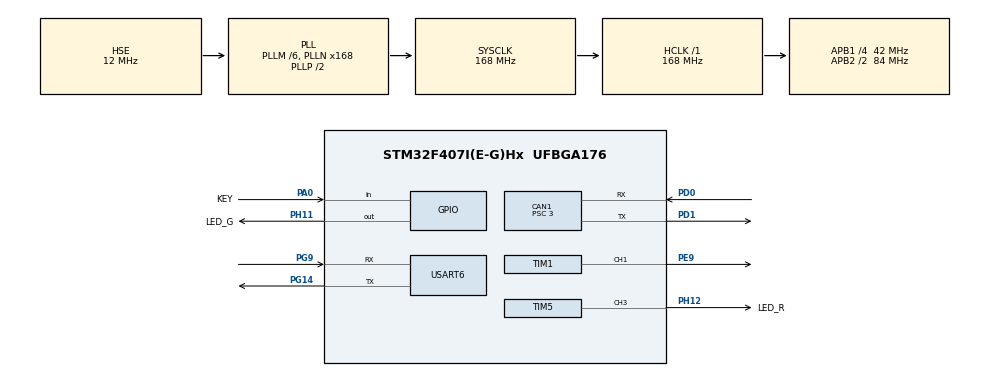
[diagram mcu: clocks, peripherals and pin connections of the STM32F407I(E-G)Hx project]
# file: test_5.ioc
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CAN1.ABOM=ENABLE
CAN1.BS1=CAN_BS1_11TQ
CAN1.BS2=CAN_BS2_2TQ
CAN1.CalculateBaudRate=1000000
CAN1.CalculateTimeBit=1000
CAN1.CalculateTimeQuantum=71.42857142857143
CAN1.NART=ENABLE
CAN1.Prescaler=3
Dma.Request0=USART6_RX
Dma.USART6_RX.0.Direction=DMA_PERIPH_TO_MEMORY
Dma.USART6_RX.0.FIFOMode=DMA_FIFOMODE_DISABLE
Dma.USART6_RX.0.Instance=DMA2_Stream1
Dma.USART6_RX.0.MemDataAlignment=DMA_MDATAALIGN_BYTE
Dma.USART6_RX.0.MemInc=DMA_MINC_ENABLE
Dma.USART6_RX.0.Mode=DMA_NORMAL
Dma.USART6_RX.0.PeriphDataAlignment=DMA_PDATAALIGN_BYTE
Dma.USART6_RX.0.PeriphInc=DMA_PINC_DISABLE
Dma.USART6_RX.0.Priority=DMA_PRIORITY_LOW
FREERTOS.Tasks01=motorTask,1,256,StartMotorTask,Default,NULL,Dynamic,NULL,NULL;uartTask,0,512,StartUartTask,Default,NULL,Dynamic,NULL,NULL;servoTask,0,256,StartServoTask,Default,NULL,Dynamic,NULL,NULL;ledTask,-1,256,StartLedTask,Default,NULL,Dynamic,NULL,NULL
FREERTOS.configTOTAL_HEAP_SIZE=24576
Mcu.Family=STM32F4
Mcu.Name=STM32F407I(E-G)Hx
Mcu.Package=UFBGA176
NVIC.CAN1_RX0_IRQn=true\:5\:0\:false\:false\:true\:true\:true\:true\:true
NVIC.DMA2_Stream1_IRQn=true\:5\:0\:false\:false\:true\:true\:false\:true\:true
NVIC.PriorityGroup=NVIC_PRIORITYGROUP_4
NVIC.TIM6_DAC_IRQn=true\:15\:0\:false\:false\:true\:true\:false\:true\:true
NVIC.USART6_IRQn=true\:5\:0\:false\:false\:true\:true\:false\:true\:true
PA0.GPIO_Label=KEY
PA0.GPIO_PuPd=GPIO_PULLUP
PA0.Signal=GPIO_Input
PA13.Mode=Serial_Wire
PA13.Signal=SYS_JTMS-SWDIO
PA14.Mode=Serial_Wire
PA14.Signal=SYS_JTCK-SWCLK
PD0.Mode=CAN_Activate
PD0.Signal=CAN1_RX
PD1.Mode=CAN_Activate
PD1.Signal=CAN1_TX
PE9.Signal=S_TIM1_CH1
PG14.Mode=Asynchronous
PG14.Signal=USART6_TX
PG9.Mode=Asynchronous
PG9.Signal=USART6_RX
PH0-OSC_IN.Mode=HSE-External-Oscillator
PH0-OSC_IN.Signal=RCC_OSC_IN
PH1-OSC_OUT.Mode=HSE-External-Oscillator
PH1-OSC_OUT.Signal=RCC_OSC_OUT
PH11.GPIO_Label=LED_G
PH11.Signal=GPIO_Output
PH12.GPIO_Label=LED_R
PH12.Signal=S_TIM5_CH3
ProjectManager.HeapSize=0x200
ProjectManager.StackSize=0x400
ProjectManager.TargetToolchain=CMake
RCC.48MHZClocksFreq_Value=48000000
RCC.AHBFreq_Value=168000000
RCC.APB1CLKDivider=RCC_HCLK_DIV4
RCC.APB1Freq_Value=42000000
RCC.APB1TimFreq_Value=84000000
RCC.APB2CLKDivider=RCC_HCLK_DIV2
RCC.APB2Freq_Value=84000000
RCC.APB2TimFreq_Value=168000000
RCC.CortexFreq_Value=168000000
RCC.HCLKFreq_Value=168000000
RCC.HSE_VALUE=12000000
RCC.HSI_VALUE=16000000
RCC.LSE_VALUE=32768
RCC.PLLM=6
RCC.PLLN=168
RCC.PLLQ=7
RCC.PLLSourceVirtual=RCC_PLLSOURCE_HSE
RCC.SYSCLKFreq_VALUE=168000000
RCC.SYSCLKSource=RCC_SYSCLKSOURCE_PLLCLK
RCC.VCOOutputFreq_Value=336000000
SH.S_TIM1_CH1.0=TIM1_CH1,PWM Generation1 CH1
SH.S_TIM5_CH3.0=TIM5_CH3,PWM Generation3 CH3
TIM1.Channel-PWM\ Generation1\ CH1=TIM_CHANNEL_1
TIM1.Period=19999
TIM1.Prescaler=167
TIM1.Pulse-PWM\ Generation1\ CH1=1500
TIM5.Channel-PWM\ Generation3\ CH3=TIM_CHANNEL_3
TIM5.Period=999
TIM5.Prescaler=83
USART6.VirtualMode=VM_ASYNC
VP_FREERTOS_VS_CMSIS_V1.Mode=CMSIS_V1
VP_SYS_VS_tim6.Mode=TIM6
board=custom
FREERTOS.INCLUDE_vTaskDelayUntil=1

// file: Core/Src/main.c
/* USER CODE BEGIN Header */
/**
  ******************************************************************************
  * @file           : main.c
  * @brief          : Main program body
  ******************************************************************************
  * @attention
  *
  * Copyright (c) 2026 STMicroelectronics.
  * All rights reserved.
  *
  * This software is licensed under terms that can be found in the LICENSE file
  * in the root directory of this software component.
  * If no LICENSE file comes with this software, it is provided AS-IS.
  *
  ******************************************************************************
  */
/* USER CODE END Header */
#include "main.h"
#include "cmsis_os.h"
#include "can.h"
#include "dma.h"
#include "tim.h"
#include "usart.h"
#include "gpio.h"

/* USER CODE BEGIN Includes */
#include "motor.h"
#include "pid.h"
/* USER CODE END Includes */

void SystemClock_Config(void);
void MX_FREERTOS_Init(void);

int main(void)
{

  /* MCU Configuration--------------------------------------------------------*/

  /* Reset of all peripherals, Initializes the Flash interface and the Systick. */
  HAL_Init();

  /* Configure the system clock */
  SystemClock_Config();

  /* Initialize all configured peripherals */
  MX_GPIO_Init();
  MX_DMA_Init();
  MX_CAN1_Init();
  MX_USART6_UART_Init();
  MX_TIM1_Init();
  MX_TIM5_Init();

  /* Call init function for freertos objects (in cmsis_os2.c) */
  MX_FREERTOS_Init();

  /* Start scheduler */
  osKernelStart();

  /* We should never get here as control is now taken by the scheduler */

  /* Infinite loop */
  while (1)
  {

  }
}

void SystemClock_Config(void)
{
  RCC_OscInitTypeDef RCC_OscInitStruct = {0};
  RCC_ClkInitTypeDef RCC_ClkInitStruct = {0};

  /** Configure the main internal regulator output voltage
  */
  __HAL_RCC_PWR_CLK_ENABLE();
  __HAL_PWR_VOLTAGESCALING_CONFIG(PWR_REGULATOR_VOLTAGE_SCALE1);

  /** Initializes the RCC Oscillators according to the specified parameters
  * in the RCC_OscInitTypeDef structure.
  */
  RCC_OscInitStruct.OscillatorType = RCC_OSCILLATORTYPE_HSE;
  RCC_OscInitStruct.HSEState = RCC_HSE_ON;
  RCC_OscInitStruct.PLL.PLLState = RCC_PLL_ON;
  RCC_OscInitStruct.PLL.PLLSource = RCC_PLLSOURCE_HSE;
  RCC_OscInitStruct.PLL.PLLM = 6;
  RCC_OscInitStruct.PLL.PLLN = 168;
  RCC_OscInitStruct.PLL.PLLP = RCC_PLLP_DIV2;
  RCC_OscInitStruct.PLL.PLLQ = 7;
  if (HAL_RCC_OscConfig(&RCC_OscInitStruct) != HAL_OK)
  {
    Error_Handler();
  }

  /** Initializes the CPU, AHB and APB buses clocks
  */
  RCC_ClkInitStruct.ClockType = RCC_CLOCKTYPE_HCLK|RCC_CLOCKTYPE_SYSCLK
                              |RCC_CLOCKTYPE_PCLK1|RCC_CLOCKTYPE_PCLK2;
  RCC_ClkInitStruct.SYSCLKSource = RCC_SYSCLKSOURCE_PLLCLK;
  RCC_ClkInitStruct.AHBCLKDivider = RCC_SYSCLK_DIV1;
  RCC_ClkInitStruct.APB1CLKDivider = RCC_HCLK_DIV4;
  RCC_ClkInitStruct.APB2CLKDivider = RCC_HCLK_DIV2;

  if (HAL_RCC_ClockConfig(&RCC_ClkInitStruct, FLASH_LATENCY_5) != HAL_OK)
  {
    Error_Handler();
  }
}

void Error_Handler(void)
{
  __disable_irq();
  while (1)
  {
  }
}

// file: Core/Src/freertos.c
/* USER CODE BEGIN Header */
/**
  ******************************************************************************
  * File Name          : freertos.c
  * Description        : Code for freertos applications
  ******************************************************************************
  * @attention
  *
  * Copyright (c) 2026 STMicroelectronics.
  * All rights reserved.
  *
  * This software is licensed under terms that can be found in the LICENSE file
  * in the root directory of this software component.
  * If no LICENSE file comes with this software, it is provided AS-IS.
  *
  ******************************************************************************
  */
/* USER CODE END Header */

#include "FreeRTOS.h"
#include "task.h"
#include "main.h"
#include "cmsis_os.h"

/* USER CODE BEGIN Includes */
#include "app_tasks.h"
/* USER CODE END Includes */

osThreadId motorTaskHandle;
osThreadId uartTaskHandle;
osThreadId servoTaskHandle;
osThreadId ledTaskHandle;

void StartMotorTask(void const * argument);
void StartUartTask(void const * argument);
void StartServoTask(void const * argument);
void StartLedTask(void const * argument);

void MX_FREERTOS_Init(void); /* (MISRA C 2004 rule 8.1) */

/* GetIdleTaskMemory prototype (linked to static allocation support) */
void vApplicationGetIdleTaskMemory( StaticTask_t **ppxIdleTaskTCBBuffer, StackType_t **ppxIdleTaskStackBuffer, uint32_t *pulIdleTaskStackSize );

/* USER CODE BEGIN GET_IDLE_TASK_MEMORY */
static StaticTask_t xIdleTaskTCBBuffer;
static StackType_t xIdleStack[configMINIMAL_STACK_SIZE];

void vApplicationGetIdleTaskMemory( StaticTask_t **ppxIdleTaskTCBBuffer, StackType_t **ppxIdleTaskStackBuffer, uint32_t *pulIdleTaskStackSize )
{
  *ppxIdleTaskTCBBuffer = &xIdleTaskTCBBuffer;
  *ppxIdleTaskStackBuffer = &xIdleStack[0];
  *pulIdleTaskStackSize = configMINIMAL_STACK_SIZE;
  /* place for user code */
}
/* USER CODE END GET_IDLE_TASK_MEMORY */

void MX_FREERTOS_Init(void) {

  /* Create the thread(s) */

  /* definition and creation of motorTask */
  osThreadDef(motorTask, StartMotorTask, osPriorityAboveNormal, 0, 256);
  motorTaskHandle = osThreadCreate(osThread(motorTask), NULL);

  /* definition and creation of uartTask */
  osThreadDef(uartTask, StartUartTask, osPriorityNormal, 0, 512);
  uartTaskHandle = osThreadCreate(osThread(uartTask), NULL);

  /* definition and creation of servoTask */
  osThreadDef(servoTask, StartServoTask, osPriorityNormal, 0, 256);
  servoTaskHandle = osThreadCreate(osThread(servoTask), NULL);

  /* definition and creation of ledTask */
  osThreadDef(ledTask, StartLedTask, osPriorityBelowNormal, 0, 256);
  ledTaskHandle = osThreadCreate(osThread(ledTask), NULL);

}

/* USER CODE BEGIN Header_StartMotorTask */
/// @brief 按固定周期计算速度环PID并发送电机控制量
/// @param argument 未使用的任务参数
/* USER CODE END Header_StartMotorTask */
void StartMotorTask(void const * argument)
{
  /* USER CODE BEGIN StartMotorTask */
  (void)argument;
  App_Motor_Task();
  /* USER CODE END StartMotorTask */
}

/* USER CODE BEGIN Header_StartUartTask */
/// @brief 处理串口命令并定时反馈实际转速
/// @param argument 未使用的任务参数
/* USER CODE END Header_StartUartTask */
void StartUartTask(void const * argument)
{
  /* USER CODE BEGIN StartUartTask */
  (void)argument;
  App_UART_Task();
  /* USER CODE END StartUartTask */
}

/* USER CODE BEGIN Header_StartServoTask */
/// @brief 检查按键并更新舵机目标角度
/// @param argument 未使用的任务参数
/* USER CODE END Header_StartServoTask */
void StartServoTask(void const * argument)
{
  /* USER CODE BEGIN StartServoTask */
  (void)argument;
  App_Servo_Task();
  /* USER CODE END StartServoTask */
}

/* USER CODE BEGIN Header_StartLedTask */
/// @brief 根据电机在线状态更新红绿灯
/// @param argument 未使用的任务参数
/* USER CODE END Header_StartLedTask */
void StartLedTask(void const * argument)
{
  /* USER CODE BEGIN StartLedTask */
  (void)argument;
  App_LED_Task();
  /* USER CODE END StartLedTask */
}
